# R7FA4L1BD register map
Vendor: Renesas Electronics Corporation; Series: RA4; File version: 0.90.02
CPU: CM33 r0p4, little endian, MPU, FPU, VTOR, 4 interrupt priority bits, 96 interrupts
Registers are 32-bit, read-write, reset 0x0 unless marked. A register's access mark holds for its fields unless they carry their own. Offsets are from the block's base; [hi:lo] are bit positions; {n}, {i} and the like mark numbered series; 'fields as' and 'values as' point back to an identical list.

## SCI1 — Serial Communication Interface 1
Base 0x40118100
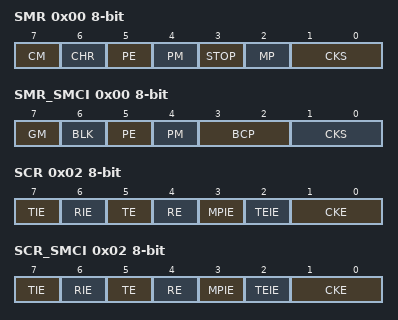
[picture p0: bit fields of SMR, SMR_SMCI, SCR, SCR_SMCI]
0x00 SMR 8-bit — Serial Mode Register for Non-Smart Card Interface Mode (SCMR.SMIF = 0)
  [7] CM — Communication Mode
    0=Asynchronous mode or simple IIC mode; 1=Clock synchronous mode or simple SPI mode
  [6] CHR — Character Length
    0=SCMR.CHR1 = 0: Transmit/receive in 9-bit data length SCMR.CHR1 = 1: Transmit/receive in 8-bit data length (initial value); 1=SCMR.CHR1 = 0: Transmit/receive in 9-bit data length SCMR.CHR1 = 1: Transmit/receive in 7-bit data length
  [5] PE — Parity Enable
    0=When transmitting: Do not add parity bit When receiving: Do not check parity bit; 1=When transmitting: Add parity bit When receiving: Check parity bit
  [4] PM — Parity Mode
    0=Even parity; 1=Odd parity
  [3] STOP — Stop Bit Length
    0=1 stop bit; 1=2 stop bits
  [2] MP — Multi-Processor Mode
    0=Disable multi-processor communications function; 1=Enable multi-processor communications function
  [1:0] CKS — Clock Select
    0=PCLK clock (n = 0); 1=PCLK/4 clock (n = 1); 2=PCLK/16 clock (n = 2); 3=PCLK/64 clock (n = 3)
0x00 SMR_SMCI 8-bit (alternate view of SMR) — Serial Mode Register for Smart Card Interface Mode (SCMR.SMIF = 1)
  [7] GM — GSM Mode
    0=Normal mode operation; 1=GSM mode operation
  [6] BLK — Block Transfer Mode
    0=Normal mode operation; 1=Block transfer mode operation
  [5] PE — Parity Enable
  [4] PM — Parity Mode
    0=Even parity; 1=Odd parity
  [3:2] BCP — Base Clock Pulse
  [1:0] CKS — Clock Select
    values as SMR.CKS
0x01 BRR 8-bit reset 0xFF — Bit Rate Register
0x02 SCR 8-bit — Serial Control Register for Non-Smart Card Interface Mode (SCMR.SMIF = 0)
  [7] TIE — Transmit Interrupt Enable
    0=Disable SCIn_TXI interrupt requests; 1=Enable SCIn_TXI interrupt requests
  [6] RIE — Receive Interrupt Enable
    0=Disable SCIn_RXI and SCIn_ERI interrupt requests; 1=Enable SCIn_RXI and SCIn_ERI interrupt requests
  [5] TE — Transmit Enable
    0=Disable serial transmission; 1=Enable serial transmission
  [4] RE — Receive Enable
    0=Disable serial reception; 1=Enable serial reception
  [3] MPIE — Multi-Processor Interrupt Enable
    0=Normal reception; 1=When data with the multi-processor bit set to 0 is received, the data is not read, and setting the status flags RDRF, ORER, and FER in SSR to 1 and the status flags SYER, PFER, and SBER in MESR are disabled. When data with the multi-processor bit set to 1 is received, the MPIE bit is automatically set to 0, and normal reception is resumed.
  [2] TEIE — Transmit End Interrupt Enable
    0=Disable SCIn_TEI interrupt requests; 1=Enable SCIn_TEI interrupt requests
  [1:0] CKE — Clock Enable
    0=In asynchronous mode, the SCKn pin is available for use as an I/O port based on the I/O port settings. In clock synchronous mode, the SCKn pin functions as the clock output pin.; 1=In asynchronous mode, a clock with the same frequency as the bit rate is output from the SCKn pin. In clock synchronous mode, the SCKn pin functions as the clock output pin.; other=Others (In asynchronous mode, input a clock with a frequency 16 times the bit rate from the SCKn pin when the SEMR.ABCS bit is 0. Input a clock signal with a frequency eight times the bit rate when the SEMR.ABCS bit is 1. The SCKn pin is available for use as an I/O port based on the I/O port settings when the GPT clock is used. In clock synchronous mode, the SCKn pin functions as the clock input pin.)
0x02 SCR_SMCI 8-bit (alternate view of SCR) — Serial Control Register for Smart Card Interface Mode (SCMR.SMIF = 1)
  [7] TIE — Transmit Interrupt Enable
    values as SCR.TIE
  [6] RIE — Receive Interrupt Enable
    values as SCR.RIE
  [5] TE — Transmit Enable
    0=Disable serial transmission; 1=Enable serial transmission
  [4] RE — Receive Enable
    0=Disable serial reception; 1=Enable serial reception
  [3] MPIE — Multi-Processor Interrupt Enable
  [2] TEIE — Transmit End Interrupt Enable
  [1:0] CKE — Clock Enable
    0=When SMR_SMCI.GM = 0: Disable output The SCKn pin is available for use as an I/O port if set up in the I/O port settings When SMR_SMCI.GM = 1: Fix output low; 1=When SMR_SMCI.GM = 0: Output clock When SMR_SMCI.GM = 1: Output clock; 2=When SMR_SMCI.GM = 0: Setting prohibited When SMR_SMCI.GM = 1: Fix output high; 3=When SMR_SMCI.GM = 0: Setting prohibited When SMR_SMCI.GM = 1: Output clock
0x03 TDR 8-bit reset 0xFF — Transmit Data Register
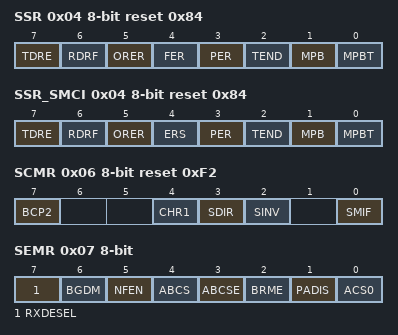
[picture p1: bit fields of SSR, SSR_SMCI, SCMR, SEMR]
0x04 SSR 8-bit reset 0x84 — Serial Status Register for Non-Smart Card Interface and Non-FIFO Mode (SCMR.SMIF = 0, FCR.FM = 0, and MMR.MANEN = 0)
  [7] TDRE — Transmit Data Empty Flag
    0=Transmit data in TDR register; 1=No transmit data in TDR register
  [6] RDRF — Receive Data Full Flag
    0=No received data in RDR register; 1=Received data in RDR register
  [5] ORER — Overrun Error Flag
    0=No overrun error occurred; 1=Overrun error occurred
  [4] FER — Framing Error Flag
    0=No framing error occurred; 1=Framing error occurred
  [3] PER — Parity Error Flag
    0=No parity error occurred; 1=Parity error occurred
  [2] TEND ro — Transmit End Flag
    0=A character is being transmitted; 1=Character transfer is complete
  [1] MPB ro — Multi-Processor
    0=Data transmission cycle; 1=ID transmission cycle
  [0] MPBT — Multi-Processor Bit Transfer
    0=Data transmission cycle; 1=ID transmission cycle
0x04 SSR_SMCI 8-bit reset 0x84 (alternate view of SSR) — Serial Status Register for Smart Card Interface Mode (SCMR.SMIF = 1, and MMR.MANEN = 0)
  [7] TDRE — Transmit Data Empty Flag
    values as SSR.TDRE
  [6] RDRF — Receive Data Full Flag
    values as SSR.RDRF
  [5] ORER — Overrun Error Flag
    0=No overrun error occurred; 1=Overrun error occurred
  [4] ERS — Error Signal Status Flag
    0=No low error signal response; 1=Low error signal response occurred
  [3] PER — Parity Error Flag
    0=No parity error occurred; 1=Parity error occurred
  [2] TEND ro — Transmit End Flag
    values as SSR.TEND
  [1] MPB ro — Multi-Processor
  [0] MPBT — Multi-Processor Bit Transfer
0x05 RDR 8-bit ro — Receive Data Register
0x06 SCMR 8-bit reset 0xF2 — Smart Card Mode Register
  [7] BCP2 — Base Clock Pulse 2
  [4] CHR1 — Character Length 1
    0=SMR.CHR = 0: Transmit/receive in 9-bit data length SMR.CHR = 1: Transmit/receive in 9-bit data length; 1=SMR.CHR = 0: Transmit/receive in 8-bit data length (initial value) SMR.CHR = 1: Transmit/receive in 7-bit data length
  [3] SDIR — Transmitted/Received Data Transfer Direction
    0=Transfer LSB-first; 1=Transfer MSB-first
  [2] SINV — Transmitted/Received Data Invert
    0=TDR contents are transmitted as they are. Received data is stored as received in the RDR register.; 1=TDR register contents are inverted before transmission. Receive data is stored in inverted form in the RDR register.
  [0] SMIF — Smart Card Interface Mode Select
    0=Non-smart card interface mode (asynchronous mode, clock synchronous mode, simple SPI mode, or simple IIC mode); 1=Smart card interface mode
0x07 SEMR 8-bit — Simple LIN Mode Register
  [7] RXDESEL — Asynchronous Start Bit Edge Detection Select
    0=Detect low level on RXDn pin as start bit; 1=Detect falling edge of RXDn pin as start bit
  [6] BGDM — Baud Rate Generator Double-Speed Mode Select
    0=Output clock from baud rate generator with normal frequency; 1=Output clock from baud rate generator with doubled frequency
  [5] NFEN — Digital Noise Filter Function Enable
    0=In asynchronous mode: Disable noise cancellation function for RXDn input signal In simple I2C mode: Disable noise cancellation function for SCLn and SDAn input signals; 1=In asynchronous mode: Enable noise cancellation function for RXDn input signal In simple I2C mode: Enable noise cancellation function for SCLn and SDAn input signals
  [4] ABCS — Asynchronous Mode Base Clock Select
    0=Select 16 base clock cycles for 1-bit period; 1=Select 8 base clock cycles for 1-bit period
  [3] ABCSE — Asynchronous Mode Extended Base Clock Select 1
    0=Clock cycles for 1-bit period determined by combination of the BGDM and ABCS bits in the SEMR register; 1=Baud rate is 6 base clock cycles for 1-bit period These bits for the other SCI channels than SCIn (n = 0, 3 to 5, 9) are reserved
  [2] BRME — Bit Rate Modulation Enable
    0=Disable bit rate modulation function; 1=Enable bit rate modulation function
  [1] PADIS — Preamble function Disable
    0=Preamble output function is enabled; 1=Preamble output function is disabled These bits for the other SCI channels than SCIn (n = 0, 3 to 5, 9) are reserved
  [0] ACS0 — Asynchronous Mode Clock Source Select
    0=External clock input; 1=Logical AND of compare matches output from the internal GPT. These bit for the other SCI channels than SCIn (n = 1) are reserved.
0x08 SNFR 8-bit — Noise Filter Setting Register
  [2:0] NFCS — Noise Filter Clock Select
    0=In asynchronous mode: Use clock signal divided by 1 with noise filter In simple I2C mode: Setting prohibited; 1=In asynchronous mode: Setting prohibited In simple I2C mode: Use clock signal divided by 1 with noise filter; 2=In asynchronous mode: Setting prohibited In simple I2C mode: Use clock signal divided by 2 with noise filter; 3=In asynchronous mode: Setting prohibited In simple I2C mode: Use clock signal divided by 4 with noise filter; 4=In asynchronous mode: Setting prohibited In simple I2C mode: Use clock signal divided by 8 with noise filter; other=Others (Setting prohibited)
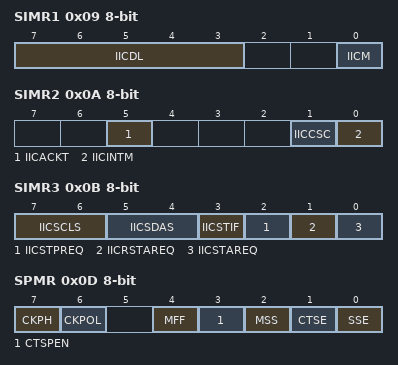
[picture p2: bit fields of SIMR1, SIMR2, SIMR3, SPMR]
0x09 SIMR1 8-bit — IIC Mode Register 1
  [7:3] IICDL — SDAn Delay Output Select
    0=No output delay; other=Others ((IICDL - 1) to (IICDL) cycles)
  [0] IICM — Simple IIC Mode Select
    0=SCMR.SMIF = 0: Asynchronous mode (including multi-processor mode), clock synchronous mode, or simple SPI mode SCMR.SMIF = 1: Smart card interface mode; 1=SCMR.SMIF = 0: Simple IIC mode SCMR.SMIF = 1: Setting prohibited
0x0A SIMR2 8-bit — IIC Mode Register 2
  [5] IICACKT — ACK Transmission Data
    0=ACK transmission; 1=NACK transmission and ACK/NACK reception
  [1] IICCSC — Clock Synchronization
    0=Do not synchronize with clock signal; 1=Synchronize with clock signal
  [0] IICINTM — IIC Interrupt Mode Select
    0=Use ACK/NACK interrupts; 1=Use reception and transmission interrupts
0x0B SIMR3 8-bit — IIC Mode Register 3
  [7:6] IICSCLS — SCLn Output Select
    0=Output serial clock; 1=Generate start, restart, or stop condition; 2=Output low on SCLn pin; 3=Drive SCLn pin to high-impedance state
  [5:4] IICSDAS — SDAn Output Select
    0=Output serial data; 1=Generate start, restart, or stop condition; 2=Output low on SDAn pin; 3=Drive SDAn pin to high-impedance state
  [3] IICSTIF — Issuing of Start, Restart, or Stop Condition Completed Flag
    0=No requests are being made for generating conditions, or a condition is being generated; 1=Generation of start, restart, or stop condition is complete. When 0 is written to IICSTIF, it is set to 0
  [2] IICSTPREQ — Stop Condition Generation
    0=Do not generate stop condition; 1=Generate stop condition
  [1] IICRSTAREQ — Restart Condition Generation
    0=Do not generate restart condition; 1=Generate restart condition
  [0] IICSTAREQ — Start Condition Generation
    0=Do not generate start condition; 1=Generate start condition
0x0C SISR 8-bit ro — IIC Status Register
  [0] IICACKR — ACK Reception Data Flag
    0=ACK received; 1=NACK received
0x0D SPMR 8-bit — SPI Mode Register
  [7] CKPH — Clock Phase Select
    0=Do not delay clock; 1=Delay clock
  [6] CKPOL — Clock Polarity Select
    0=Do not invert clock polarity; 1=Invert clock polarity
  [4] MFF — Mode Fault Flag
    0=No mode fault error; 1=Mode fault error
  [3] CTSPEN — CTS External Pin Enable
    0=Alternate setting to use CTS and RTS functions as either one terminal; 1=Dedicated setting for separately using CTS and RTS functions with 2 terminals These bits for the other SCI channels than SCIn (n = 0, 3 to 5, 9) are reserved
  [2] MSS — Master Slave Select
    0=Transmit through TXDn pin and receive through RXDn pin (master mode); 1=Receive through TXDn pin and transmit through RXDn pin (slave mode)
  [1] CTSE — CTS Enable
    0=Disable CTS function (enable RTS output function); 1=Enable CTS function
  [0] SSE — SSn Pin Function Enable
    0=Disable SSn pin function; 1=Enable SSn pin function
0x0E TDRHL 16-bit reset 0xFFFF (alternate view of FTDRHL) — Transmit Data Register for Non-Manchester Mode (MMR.MANEN = 0)
  [8:0] TDAT — Serial Transmit Data
0x10 RDRHL 16-bit ro (alternate view of FRDRHL) — Receive Data Register for Non-Manchester Mode (MMR.MANEN = 0)
  [8:0] RDAT — Serial Receive Data
0x12 MDDR 8-bit reset 0xFF — Modulation Duty Register
0x20 ESMER 8-bit — Simple LIN Mode Enable Register
  [0] ESME — Simple LIN Mode Enable
    0=The simple LIN mode is disabled; 1=The simple LIN mode is enabled
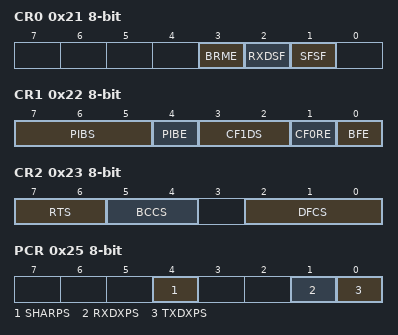
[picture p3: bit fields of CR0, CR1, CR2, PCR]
0x21 CR0 8-bit — Control Register 0
  [3] BRME — Bit Rate Measurement Enable
    0=Measurement of bit rate is disabled; 1=Measurement of bit rate is enabled
  [2] RXDSF ro — RXDXn Input Status Flag
    0=RXDXn input is enabled; 1=RXDXn input is disabled
  [1] SFSF ro — Start Frame Status Flag
    0=Start frame detection function is disabled; 1=Start frame detection function is enabled
0x22 CR1 8-bit — Control Register 1
  [7:5] PIBS — Priority Interrupt Bit Select
    0=0th bit of Control Field 1; 1=1st bit of Control Field 1; 2=2nd bit of Control Field 1; 3=3rd bit of Control Field 1; {v}={v}th bit of Control Field 1 (v=4..7)
  [4] PIBE — Priority Interrupt Bit Enable
    0=The priority interrupt bit is disabled; 1=The priority interrupt bit is enabled
  [3:2] CF1DS — Control Field 1 Data Register Select
    0=Selects comparison with the value in PCF1DR; 1=Selects comparison with the value in SCF1DR; 2=Selects comparison with the values in PCF1DR and SCF1DR; 3=Setting prohibited
  [1] CF0RE — Control Field 0 Reception Enable
    0=Reception of Control Field 0 is disabled; 1=Reception of Control Field 0 is enabled
  [0] BFE — Break Field Enable
    0=Break Field detection is disabled; 1=Break Field detection is enabled
0x23 CR2 8-bit — Control Register 2
  [7:6] RTS — RXDXn Reception Sampling Timing Select
    0=Rising edge of the 8th cycle of SCI base clock; 1=Rising edge of the 10th cycle of SCI base clock; 2=Rising edge of the 12th cycle of SCI base clock; 3=Rising edge of the 14th cycle of SCI base clock
  [5:4] BCCS — Bus Collision Detection Clock Select
    0=SCI base clock; 1=SCI base clock frequency divided by 2; 2=SCI base clock frequency divided by 4; 3=Setting prohibited
  [2:0] DFCS — RXDXn Signal Digital Filter Clock Select
    0=Filter is disabled; 1=Filter clock is SCI base clock; 2=Filter clock is PCLK/8; 3=Filter clock is PCLK/16; 4=Filter clock is PCLK/32; 5=Filter clock is PCLK/64; 6=Filter clock is PCLK/128; 7=Setting prohibited
0x24 CR3 8-bit — Control Register 3
  [0] SDST — Start Frame Detection Start
    0=Detection of start frame is not performed; 1=Detection of start frame is performed
0x25 PCR 8-bit — Port Control Register
  [4] SHARPS — TXDXn/RXDXn Pin Multiplexing Select
    0=The TXDXn and RXDXn pins are independent; 1=The TXDXn and RXDXn signals are multiplexed on the same pin
  [1] RXDXPS — RXDXn Signal Polarity Select
    0=The polarity of RXDXn signal is not inverted for input; 1=The polarity of RXDXn signal is inverted for input
  [0] TXDXPS — TXDXn Signal Polarity Select
    0=The polarity of TXDXn signal is not inverted for output; 1=The polarity of TXDXn signal is inverted for output
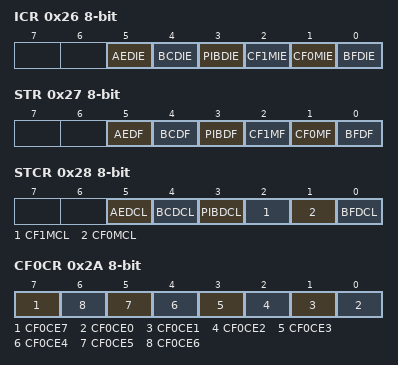
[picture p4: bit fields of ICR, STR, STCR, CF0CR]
0x26 ICR 8-bit — Interrupt Control Register
  [5] AEDIE — Valid Edge Detected Interrupt Enable
    0=Interrupts on detection of a valid edge are disabled; 1=Interrupts on detection of a valid edge are enabled
  [4] BCDIE — Bus Collision Detected Interrupt Enable
    0=Interrupts on detection of a bus collision are disabled; 1=Interrupts on detection of a bus collision are enabled
  [3] PIBDIE — Priority Interrupt Bit Detected Interrupt Enable
    0=Interrupts on detection of the priority interrupt bit are disabled; 1=Interrupts on detection of the priority interrupt bit are enabled
  [2] CF1MIE — Control Field 1 Match Detected Interrupt Enable
    0=Interrupts on detection of a match with Control Field 1 are disabled; 1=Interrupts on detection of a match with Control Field 1 are enabled
  [1] CF0MIE — Control Field 0 Match Detected Interrupt Enable
    0=Interrupts on detection of a match with Control Field 0 are disabled; 1=Interrupts on detection of a match with Control Field 0 are enabled
  [0] BFDIE — Break Field Low Width Detected Interrupt Enable
    0=Interrupts on detection of the low width for a Break Field are disabled; 1=Interrupts on detection of the low width for a Break Field are enabled
0x27 STR 8-bit ro — Status Register
  [5] AEDF — Valid Edge Detection Flag
  [4] BCDF — Bus Collision Detected Flag
  [3] PIBDF — Priority Interrupt Bit Detection Flag
  [2] CF1MF — Control Field 1 Match Flag
  [1] CF0MF — Control Field 0 Match Flag
  [0] BFDF — Break Field Low Width Detection Flag
0x28 STCR 8-bit — Status Clear Register
  [5] AEDCL — AEDF Clear
  [4] BCDCL — BCDF Clear
  [3] PIBDCL — PIBDF Clear
  [2] CF1MCL — CF1MF Clear
  [1] CF0MCL — CF0MF Clear
  [0] BFDCL — BFDF Clear
0x29 CF0DR 8-bit — Control Field 0 Data Register
0x2A CF0CR 8-bit — Control Field 0 Compare Enable Register
  [7] CF0CE7 — Control Field 7 Bit 0 Compare Enable
    0=Comparison with bit 7 of Control Field 0 is disabled; 1=Comparison with bit 7 of Control Field 0 enabled
  [n] CF0CE{n} (n=0..6) — Control Field {n} Bit 0 Compare Enable
    0=Comparison with bit {n} of Control Field 0 disabled; 1=Comparison with bit {n} of Control Field 0 enabled
0x2B CF0RR 8-bit — Control Field 0 Receive Data Register
0x2C PCF1DR 8-bit — Primary Control Field 1 Data Register
0x2D SCF1DR 8-bit — Secondary Control Field 1 Data Register
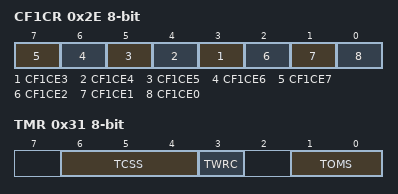
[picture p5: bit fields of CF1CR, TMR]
0x2E CF1CR 8-bit — Control Field 1 Compare Enable Register
  [n] CF1CE{n} (n=3..7) — Control Field 1 Bit {n} Compare Enable
    0=Comparison with bit {n} of Control Field 1 disabled; 1=Comparison with bit {n} of Control Field 1 enabled
  [2] CF1CE2 — Control Field 1 Bit 2 Compare Enable
    0=Comparison with bit 2 of Control Field 1 disabled; 1=Comparison with bit 2 of Control Field 1 is enabled
  [1] CF1CE1 — Control Field 1 Bit 1 Compare Enable
    0=Comparison with bit 1 of Control Field 1 disabled; 1=Comparison with bit 1 of Control Field 1 enabled
  [0] CF1CE0 — Control Field 1 Bit 0 Compare Enable
    0=Comparison with bit 0 of Control Field 1 disabled; 1=Comparison with bit 0 of Control Field 1 enabled
0x2F CF1RR 8-bit — Control Field 1 Receive Data Register
0x30 TCR 8-bit — Timer Control Register
  [0] TCST — Timer Count Start
    0=Stops the timer counting; 1=Starts the timer counting
0x31 TMR 8-bit — Timer Mode Register
  [6:4] TCSS — Timer Count Clock Source Select
    0=PCLK; 1=PCLK/2; 2=PCLK/4; 3=PCLK/8; 4=PCLK/16; 5=PCLK/32; 6=PCLK/64; 7=PCLK/128
  [3] TWRC — Counter Write Control
    0=Data is written to the reload register and counter; 1=Data is written to the reload register only
  [1:0] TOMS — Timer Operating Mode Select
    0=Timer mode; 1=Break Field low width determination mode; 2=Break Field low width output mode; 3=Setting prohibited
0x32 TPRE 8-bit reset 0xFF — Timer Prescaler Register
0x33 TCNT 8-bit reset 0xFF — Timer Count Register
